# SAM9X75D1GN2 device description
Architecture: ARM926EJ-S; Family: SAM9; Series: SAM9X7
Registers are 32-bit, read-write, reset 0x0 unless marked. A register's access mark holds for its fields unless they carry their own. Offsets are from the block's base; [hi:lo] are bit positions.

## DBGU — Debug Unit
Instances: DBGU 0xFFFFF200
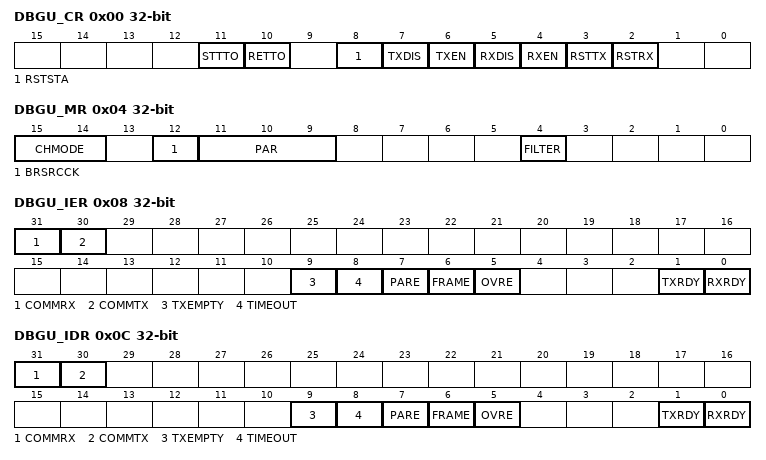
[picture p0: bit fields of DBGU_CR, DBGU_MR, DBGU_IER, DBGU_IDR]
0x00 DBGU_CR wo reset not defined — Control Register
  [11] STTTO — Start Timeout
    0=No effect; 1=Starts waiting for a character before clocking the timeout counter. Resets status bit DBGU_SR.TIMEOUT.
  [10] RETTO — Rearm Timeout
    0=No effect; 1=Restarts timeout
  [8] RSTSTA — Reset Status
    0=No effect; 1=Resets the status bits PARE, FRAME and OVRE in DBGU_SR
  [7] TXDIS — Transmitter Disable
    0=No effect; 1=The transmitter is disabled. If a character is being processed and a character has been written in DBGU_THR and RSTTX is not set, both characters are completed before the transmitter is stopped.
  [6] TXEN — Transmitter Enable
    0=No effect; 1=The transmitter is enabled if TXDIS is 0
  [5] RXDIS — Receiver Disable
    0=No effect; 1=The receiver is disabled. If a character is being processed and RSTRX is not set, the character is completed before the receiver is stopped.
  [4] RXEN — Receiver Enable
    0=No effect; 1=The receiver is enabled if RXDIS is 0
  [3] RSTTX — Reset Transmitter
    0=No effect; 1=The transmitter logic is reset and disabled. If a character is being transmitted, the transmission is aborted.
  [2] RSTRX — Reset Receiver
    0=No effect; 1=The receiver logic is reset and disabled. If a character is being received, the reception is aborted.
0x04 DBGU_MR — Mode Register
  [15:14] CHMODE — Channel Mode
    0=NORMAL (Normal mode); 1=AUTOMATIC (Automatic echo); 2=LOCAL_LOOPBACK; 3=REMOTE_LOOPBACK
  [12] BRSRCCK — Baud Rate Source Clock
    0=PERIPH_CLK (The baud rate is driven by the peripheral clock); 1=GCLK (The baud rate is driven by a PMC-programmable clock GCLK (see section Power Management Controller (PMC)).)
  [11:9] PAR — Parity Type
    0=EVEN (Even Parity); 1=ODD (Odd Parity); 2=SPACE (Space: parity forced to 0); 3=MARK (Mark: parity forced to 1); 4=NO (No parity)
  [4] FILTER — Receiver Digital Filter
    0=DISABLED (DBGU does not filter the receive line.); 1=ENABLED (DBGU filters the receive line using a three-sample filter (16x-bit clock) (2 over 3 majority).)
0x08 DBGU_IER wo reset not defined (atomic set of DBGU_IMR) — Interrupt Enable Register
  [31] COMMRX — Enable COMMRX (from ARM) Interrupt
  [30] COMMTX — Enable COMMTX (from ARM) Interrupt
  [9] TXEMPTY — Enable TXEMPTY Interrupt
  [8] TIMEOUT — Enable Timeout Interrupt
  [7] PARE — Enable Parity Error Interrupt
  [6] FRAME — Enable Framing Error Interrupt
  [5] OVRE — Enable Overrun Error Interrupt
  [1] TXRDY — Enable TXRDY Interrupt
  [0] RXRDY — Enable RXRDY Interrupt
0x0C DBGU_IDR wo reset not defined (atomic clear of DBGU_IMR) — Interrupt Disable Register
  [31] COMMRX — Disable COMMRX (from ARM) Interrupt
  [30] COMMTX — Disable COMMTX (from ARM) Interrupt
  [9] TXEMPTY — Disable TXEMPTY Interrupt
  [8] TIMEOUT — Disable Timeout Interrupt
  [7] PARE — Disable Parity Error Interrupt
  [6] FRAME — Disable Framing Error Interrupt
  [5] OVRE — Disable Overrun Error Interrupt
  [1] TXRDY — Disable TXRDY Interrupt
  [0] RXRDY — Disable RXRDY Interrupt
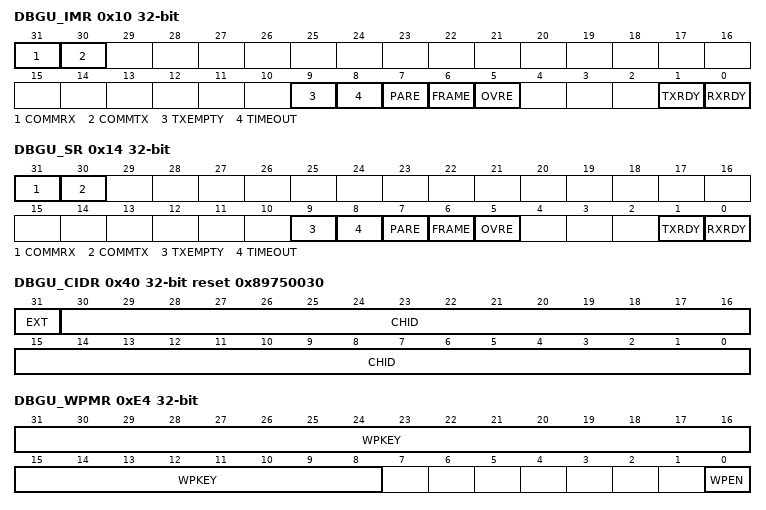
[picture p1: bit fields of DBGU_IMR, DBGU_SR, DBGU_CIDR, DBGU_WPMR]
0x10 DBGU_IMR ro — Interrupt Mask Register
  [31] COMMRX — Mask COMMRX (from ARM) Interrupt
  [30] COMMTX — Mask COMMTX (from ARM) Interrupt
  [9] TXEMPTY — Mask TXEMPTY Interrupt
  [8] TIMEOUT — Mask Timeout Interrupt
  [7] PARE — Mask Parity Error Interrupt
  [6] FRAME — Mask Framing Error Interrupt
  [5] OVRE — Mask Overrun Error Interrupt
  [1] TXRDY — Disable TXRDY Interrupt
  [0] RXRDY — Mask RXRDY Interrupt
0x14 DBGU_SR ro reset not defined — Status Register
  [31] COMMRX — Debug Communication Channel Read Status
    0=COMMRX from the ARM processor is inactive; 1=COMMRX from the ARM processor is active
  [30] COMMTX — Debug Communication Channel Write Status
    0=COMMTX from the ARM processor is inactive; 1=COMMTX from the ARM processor is active
  [9] TXEMPTY — Transmitter Empty
    0=There are characters in DBGU_THR, or characters are being processed by the transmitter, or the transmitter is disabled; 1=There are no characters in DBGU_THR and there are no characters being processed by the transmitter
  [8] TIMEOUT — Receiver Timeout
    0=There has not been any timeout since the last Start timeout command (DBGU_CR.STTTO), or the Timeout register is 0; 1=There has been a timeout since the last Start timeout command (DBGU_CR.STTTO)
  [7] PARE — Parity Error
    0=No parity error has occurred since the last RSTSTA; 1=At least one parity error has occurred since the last RSTSTA
  [6] FRAME — Framing Error
    0=No framing error has occurred since the last RSTSTA; 1=At least one framing error has occurred since the last RSTSTA
  [5] OVRE — Overrun Error
    0=No overrun error has occurred since the last RSTSTA; 1=At least one overrun error has occurred since the last RSTSTA
  [1] TXRDY — Transmitter Ready
    0=A character has been written to DBGU_THR and not yet transferred to the internal shift register, or the transmitter is disabled; 1=There is no character written to DBGU_THR that is not yet transferred to the internal shift register
  [0] RXRDY — Receiver Ready
    0=No character has been received since the last read of DBGU_RHR, or the receiver is disabled; 1=At least one complete character has been received, transferred to DBGU_RHR, and not yet read
0x18 DBGU_RHR ro — Receive Holding Register
  [7:0] RXCHR — Received Character
0x1C DBGU_THR wo reset not defined — Transmit Holding Register
  [7:0] TXCHR — Character to be Transmitted
0x20 DBGU_BRGR — Baud Rate Generator Register
  [15:0] CD — Clock Divisor
    0=Baud rate clock is disabled
0x28 DBGU_RTOR — Receiver Timeout Register
  [7:0] TO — Timeout Value
    0=The receiver timeout is disabled
0x40 DBGU_CIDR ro reset 0x89750030 — Chip ID Register
  [31] EXT — Extension Flag
    0=Chip ID has a single register definition without extension; 1=An extended Chip ID exists
  [30:0] CHID — Chip ID Value
0x44 DBGU_EXID ro reset not defined — Chip ID Extension Register
  [31:0] EXID — Chip ID Extension
0x48 DBGU_FNR — Force NTRST Register
  [0] FNTRST — Force NTRST
    0=NTRST of the ARM processor's TAP controller is driven by the power_on_reset signal; 1=NTRST of the ARM processor's TAP controller is held low
0xE4 DBGU_WPMR — Write Protection Mode Register
  [31:8] WPKEY — Write Protection Key
    0x554152=PASSWD (Writing any other value in this field aborts the write operation. Always reads as 0.)
  [0] WPEN — Write Protection Enable
    0=Disables the write protection if WPKEY corresponds to 0x554152 (DBGU in ASCII); 1=Enables the write protection if WPKEY corresponds to 0x554152 (DBGU in ASCII)
